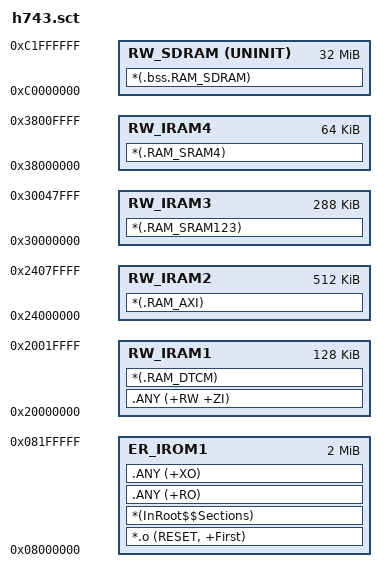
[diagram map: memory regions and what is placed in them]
LR_IROM1 0x08000000 0x00200000 { ; load region size_region
    ER_IROM1 0x08000000 0x00200000 { ; load address = execution address
        *.o (RESET, +First)
        *(InRoot$$Sections)
        .ANY (+RO)
        .ANY (+XO)
    }

    ; RW data - 128KB DTCM
    RW_IRAM1 0x20000000 0x00020000 {
        .ANY (+RW +ZI)
        *(.RAM_DTCM)
    }

    ; RW data - 512KB AXI SRAM
    RW_IRAM2 0x24000000 0x00080000 {
        *(.RAM_AXI)
    }

    ; RW data - 128KB SRAM1(0x30000000) + 128KB SRAM2(0x3002 0000) + 32KB SRAM3(0x30040000)
    RW_IRAM3 0x30000000 0x00048000 {
        *(.RAM_SRAM123)
    }

    ; RW data - 64KB SRAM4(0x38000000)
    RW_IRAM4 0x38000000 0x00010000 {
        *(.RAM_SRAM4)
    }

    ; RW data - 32 MB ERAM(0xC0000000)
    RW_SDRAM 0xC0000000 UNINIT 0x02000000 {
        *(.bss.RAM_SDRAM)
    }
}
